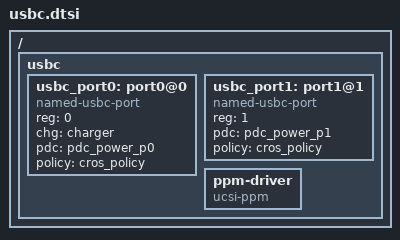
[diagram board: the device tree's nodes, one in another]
/* Copyright 2025 The ChromiumOS Authors
 * Use of this source code is governed by a BSD-style license that can be
 * found in the LICENSE file.
 */

#include <usbc-policy.dtsi>

 / {
	usbc {
		#address-cells = <1>;
		#size-cells = <0>;

		usbc_port0: port0@0 {
			compatible = "named-usbc-port";
			reg = <0>;
			chg = <&charger>;
			pdc = <&pdc_power_p0>;
			policy = <&cros_policy>;
		};
		usbc_port1: port1@1 {
			compatible = "named-usbc-port";
			reg = <1>;
			pdc = <&pdc_power_p1>;
			policy = <&cros_policy>;
		};
		ppm-driver {
			compatible = "ucsi-ppm";
		};
	};
 };
